# M475 register map
File version: 2.0.2.5
Registers are 32-bit, read-write, reset 0x0 unless marked. A register's access mark holds for its fields unless they carry their own. Offsets are from the block's base; [hi:lo] are bit positions; {n}, {i} and the like mark numbered series.

## EN0 — Encoder Input (ENC)
Base 0x400F7000
Same registers: EN1 0x400F7100
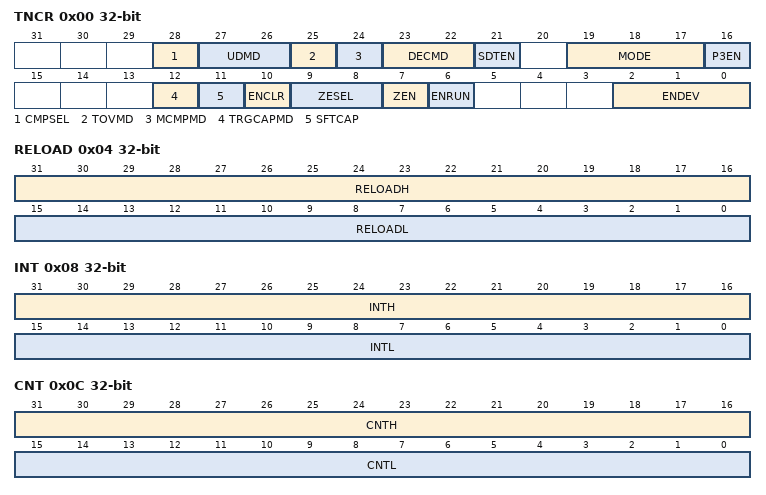
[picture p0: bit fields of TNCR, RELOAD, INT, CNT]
0x00 TNCR — Encoder Control Register
  [28] CMPSEL, [27:26] UDMD, [25] TOVMD, [24] MCMPMD, [23:22] DECMD, [21] SDTEN, [19:17] MODE, [16] P3EN, [12] TRGCAPMD, [11] SFTCAP wo, [10] ENCLR wo, [9:8] ZESEL, [7] ZEN, [6] ENRUN, [2:0] ENDEV
0x04 RELOAD — Reload Compare Register
  [31:16] RELOADH, [15:0] RELOADL
0x08 INT — INT Compare Register
  [31:16] INTH, [15:0] INTL
0x0C CNT — Counter_Capture Register
  [31:16] CNTH, [15:0] CNTL
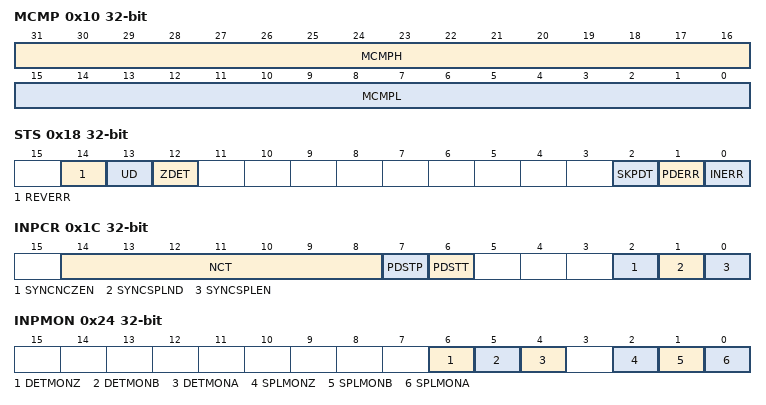
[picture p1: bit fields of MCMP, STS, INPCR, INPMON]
0x10 MCMP — MCMP Compare Register
  [31:16] MCMPH, [15:0] MCMPL
0x14 RATE — Phase Count Rate Register
  [15:0] RATE
0x18 STS ro — Status Register
  [14] REVERR, [13] UD, [12] ZDET, [2] SKPDT, [1] PDERR, [0] INERR
0x1C INPCR — Input Process Cntrol Register
  [14:8] NCT, [7] PDSTP wo, [6] PDSTT wo, [2] SYNCNCZEN, [1] SYNCSPLND, [0] SYNCSPLEN
0x20 SMPDLY — Sample Delay Register
  [7:0] SMPDLY
0x24 INPMON ro — Input Moniter Register
  [6] DETMONZ, [5] DETMONB, [4] DETMONA, [2] SPLMONZ, [1] SPLMONB, [0] SPLMONA
0x28 CLKCR — Sample Clock Control Register
  [1:0] SPLCLKS
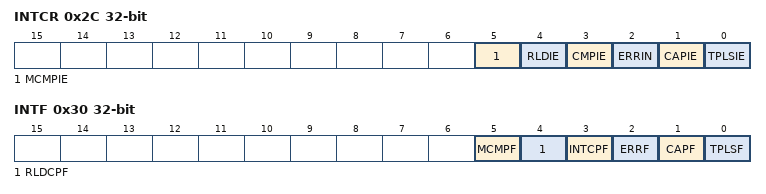
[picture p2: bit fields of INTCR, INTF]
0x2C INTCR — Interrupt Reqyest Control Register
  [5] MCMPIE, [4] RLDIE, [3] CMPIE, [2] ERRIN, [1] CAPIE, [0] TPLSIE
0x30 INTF ro — Interrupt Event Flag Register
  [5] MCMPF, [4] RLDCPF, [3] INTCPF, [2] ERRF, [1] CAPF, [0] TPLSF

## ADA — Analog-to-Digital Converter (AD)
Base 0x400FD000
Same registers: ADB 0x400FD100
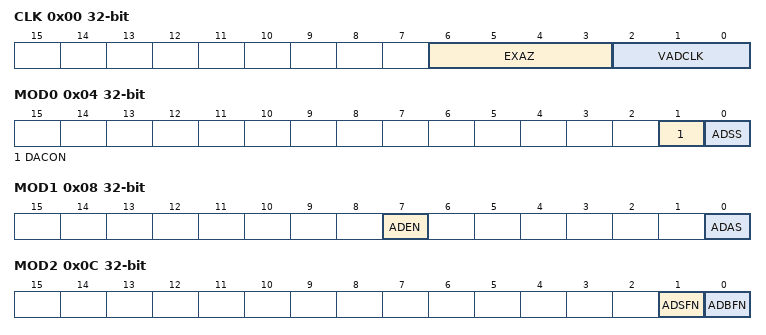
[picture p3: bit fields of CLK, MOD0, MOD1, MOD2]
0x00 CLK — AD Conversion Clock Setting Register
  [6:3] EXAZ, [2:0] VADCLK
0x04 MOD0 — AD Mode Setting Register 0
  [1] DACON, [0] ADSS wo
0x08 MOD1 — AD Mode Setting Register 1
  [7] ADEN, [0] ADAS
0x0C MOD2 ro — AD Mode Setting Register 2
  [1] ADSFN, [0] ADBFN
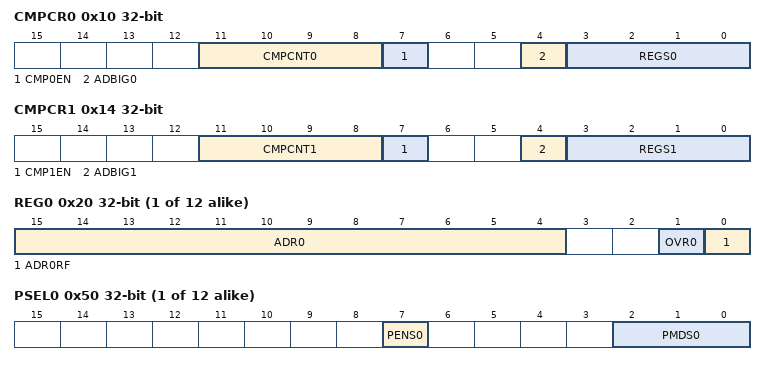
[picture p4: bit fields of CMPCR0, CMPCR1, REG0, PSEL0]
0x10 CMPCR0 — AD Monitoring Setting Register 0
  [11:8] CMPCNT0, [7] CMP0EN, [4] ADBIG0, [3:0] REGS0
0x14 CMPCR1 — AD Monitoring Setting Register 1
  [11:8] CMPCNT1, [7] CMP1EN, [4] ADBIG1, [3:0] REGS1
0x18 CMP0 — AD Conversion Result Compare Register 0
  [15:4] AD0CMP0
0x1C CMP1 — AD Conversion Result Compare Register 1
  [15:4] AD0CMP1
{0x20+4i} REG{i} ro (i=0..11) — AD Conversion Result Register {i}
  [15:4] ADR{i}, [1] OVR{i}, [0] ADR{i}RF
{0x50+4i} PSEL{i} (i=0..11) — PMD Trigger Program Number Select Register {i}
  [7] PENS{i}, [2:0] PMDS{i}
{0x80+4i} PINTS{i} (i=0..5) — PMD Trigger Interrupt Select Register {i}
  [1:0] INTSEL{i}
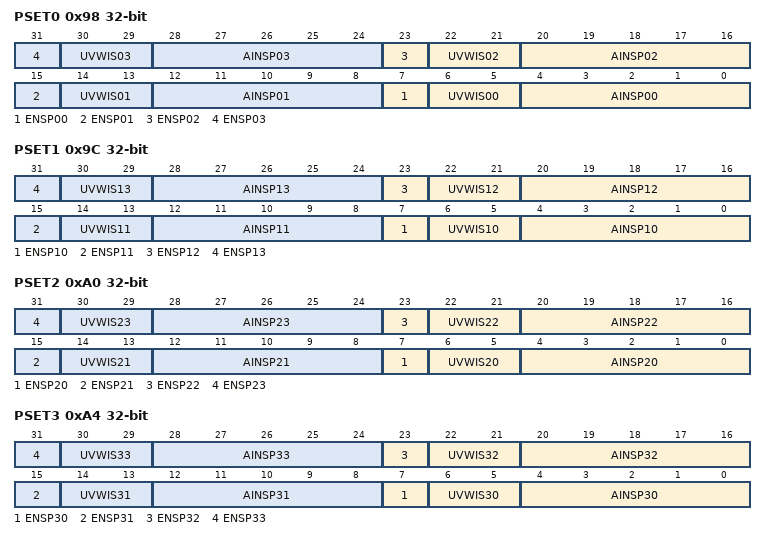
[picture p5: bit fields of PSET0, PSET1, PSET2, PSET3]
0x98 PSET0 — PMD Trigger Program Register 0
  [8n+7] ENSP{n:02} (n=0..3), [8n+6:8n+5] UVWIS{n:02} (n=0..3), [8n+4:8n] AINSP{n:02} (n=0..3)
0x9C PSET1 — PMD Trigger Program Register 1
  [8n-73] ENSP{n} (n=10..13), [8n-74:8n-75] UVWIS{n} (n=10..13), [8n-76:8n-80] AINSP{n} (n=10..13)
0xA0 PSET2 — PMD Trigger Program Register 2
  [8n-153] ENSP{n} (n=20..23), [8n-154:8n-155] UVWIS{n} (n=20..23), [8n-156:8n-160] AINSP{n} (n=20..23)
0xA4 PSET3 — PMD Trigger Program Register 3
  [8n-233] ENSP{n} (n=30..33), [8n-234:8n-235] UVWIS{n} (n=30..33), [8n-236:8n-240] AINSP{n} (n=30..33)
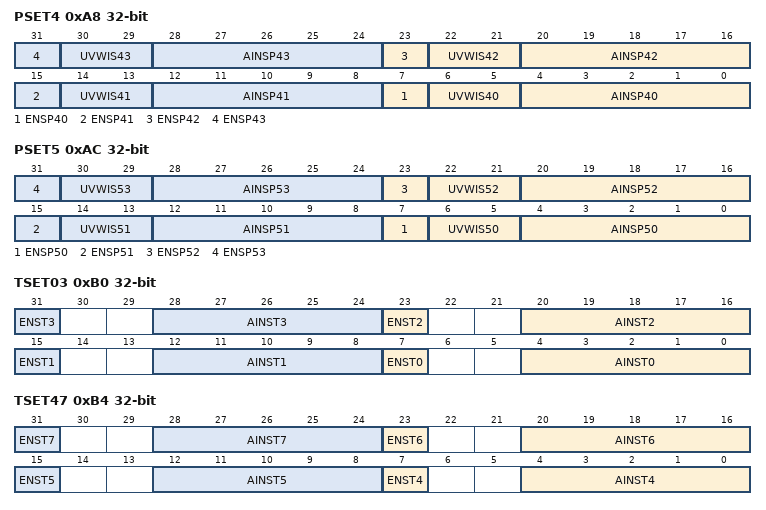
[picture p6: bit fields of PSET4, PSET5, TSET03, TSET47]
0xA8 PSET4 — PMD Trigger Program Register 4
  [8n-313] ENSP{n} (n=40..43), [8n-314:8n-315] UVWIS{n} (n=40..43), [8n-316:8n-320] AINSP{n} (n=40..43)
0xAC PSET5 — PMD Trigger Program Register 5
  [8n-393] ENSP{n} (n=50..53), [8n-394:8n-395] UVWIS{n} (n=50..53), [8n-396:8n-400] AINSP{n} (n=50..53)
0xB0 TSET03 — Timer Trigger Program Register 03
  [8n+7] ENST{n} (n=0..3), [8n+4:8n] AINST{n} (n=0..3)
0xB4 TSET47 — Timer Trigger Program Register 47
  [8n-25] ENST{n} (n=4..7), [8n-28:8n-32] AINST{n} (n=4..7)
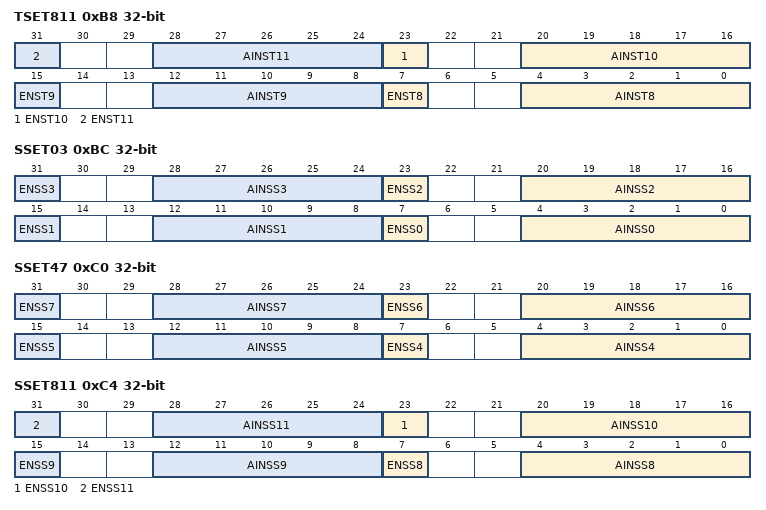
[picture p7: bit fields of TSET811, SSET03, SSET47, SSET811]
0xB8 TSET811 — Timer Trigger Program Register 811
  [8n-57] ENST{n} (n=8..11), [8n-60:8n-64] AINST{n} (n=8..11)
0xBC SSET03 — Software Trigger Program Register 03
  [8n+7] ENSS{n} (n=0..3), [8n+4:8n] AINSS{n} (n=0..3)
0xC0 SSET47 — Software Trigger Program Register 47
  [8n-25] ENSS{n} (n=4..7), [8n-28:8n-32] AINSS{n} (n=4..7)
0xC4 SSET811 — Software Trigger Program Register 811
  [8n-57] ENSS{n} (n=8..11), [8n-60:8n-64] AINSS{n} (n=8..11)
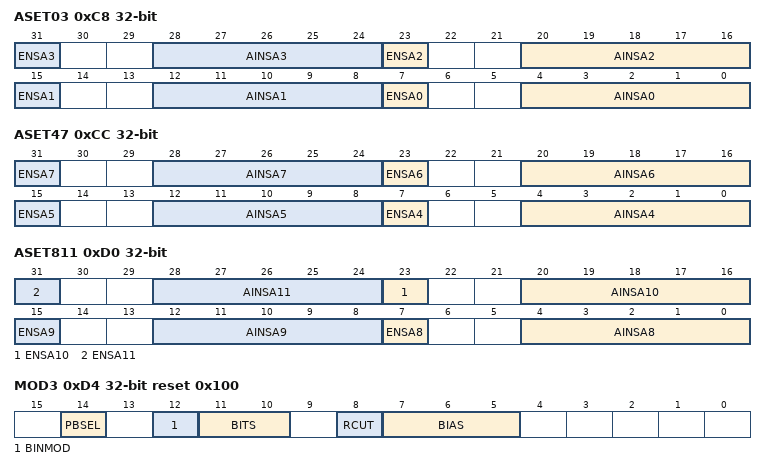
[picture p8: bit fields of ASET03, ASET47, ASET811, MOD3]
0xC8 ASET03 — Constant Conversion Program Register 03
  [8n+7] ENSA{n} (n=0..3), [8n+4:8n] AINSA{n} (n=0..3)
0xCC ASET47 — Constant Conversion Program Register 47
  [8n-25] ENSA{n} (n=4..7), [8n-28:8n-32] AINSA{n} (n=4..7)
0xD0 ASET811 — Constant Conversion Program Register 811
  [8n-57] ENSA{n} (n=8..11), [8n-60:8n-64] AINSA{n} (n=8..11)
0xD4 MOD3 reset 0x100 — Mode setting Register 3
  [14] PBSEL, [12] BINMOD, [11:10] BITS, [8] RCUT, [7:5] BIAS
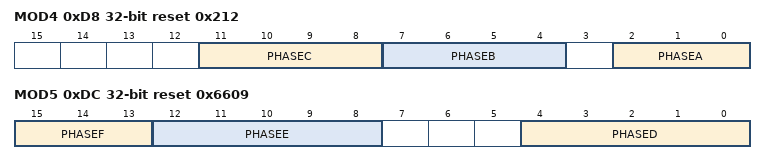
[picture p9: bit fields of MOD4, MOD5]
0xD8 MOD4 reset 0x212 — Mode setting Register 4
  [11:8] PHASEC, [7:4] PHASEB, [2:0] PHASEA
0xDC MOD5 reset 0x6609 — Mode setting Register 5
  [15:13] PHASEF, [12:8] PHASEE, [4:0] PHASED

## FC — Flash Control (FC)
Base 0x5DFF0000
0x10 SECBIT reset 0x1 — Security Bit Register
  [0] SECBIT
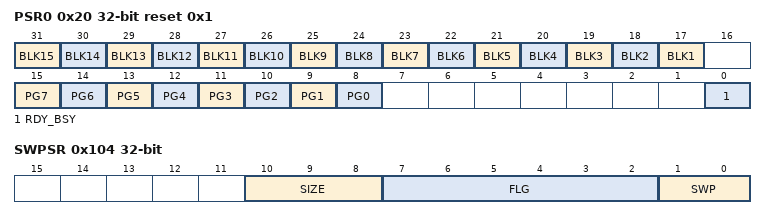
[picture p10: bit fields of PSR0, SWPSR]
0x20 PSR0 ro reset 0x1 (reset mask 0xFF) — Protect Status Register 0
  [n+16] BLK{n} (n=1..15), [n+8] PG{n} (n=0..7), [0] RDY_BSY
0x100 SR ro — Status Register
  [24] WEABORT
0x104 SWPSR ro — Swap Status Register
  [10:8] SIZE, [7:2] FLG, [1:0] SWP
0x140 AREASEL — Area Selection Register
  [2:0] AREA0
0x148 CR — Control Register
  [2:0] WEABORT
0x14C STSCLR — Status Clear Register
  [2:0] WEABORT
0x150 WCLKCR — WCLK Configuration Register
  [4:0] DIV
0x154 PROGCR — Program Counter Configuration Register
  [1:0] CNT
0x158 ERASECR reset 0x6 — Erase Counter Configuration Register
  [3:0] CNT
